# f2838x_cm_aes_ss_regs register map
Vendor: Texas Instruments
Peripheral module from a debugger description file (folder C2000).
Address unit: 16 bits
Registers are 32-bit, read-write, no defined reset value unless marked. A register's access mark holds for its fields unless they carry their own. Offsets are as the file gives them; lines under a group give offsets from that group; [hi:lo] are bit positions; {n}, {i} and the like mark numbered series; 'fields as' and 'values as' point back to an identical list; <NAME> marks a mode.

## AES_SS_REGS — AES SS Registers
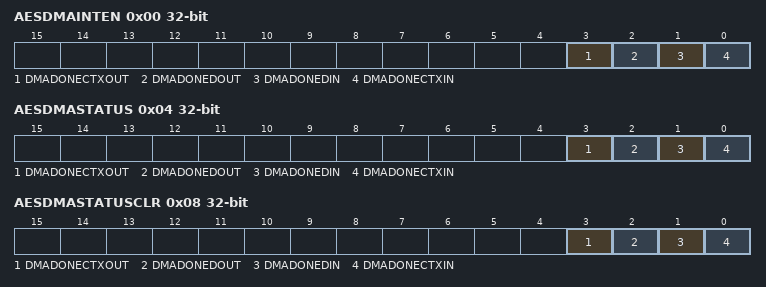
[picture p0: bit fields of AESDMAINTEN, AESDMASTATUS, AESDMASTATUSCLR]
0x00 AESDMAINTEN — DMA Done Interrupt enable register
  [3] DMADONECTXOUT — Enable bit for DMADONECTXOUT
  [2] DMADONEDOUT — Enable bit for DMADONEDOUT
  [1] DMADONEDIN — Enable bit for DMADONEDIN
  [0] DMADONECTXIN — Enable bit for DMADONECTXIN
0x04 AESDMASTATUS ro — DMA Done Interrupt status register
  [3] DMADONECTXOUT — Status bit for DMADONECTXOUT
  [2] DMADONEDOUT — Status bit for DMADONEDOUT
  [1] DMADONEDIN — Status bit for DMADONEDIN
  [0] DMADONECTXIN — Status bit for DMADONECTXIN
0x08 AESDMASTATUSCLR — DMA Done Interrupt status clear register
  [3] DMADONECTXOUT — Clear bit for AESDMASTSTAUS.DMADONECTXOUT
  [2] DMADONEDOUT — Clear bit for AESDMASTSTAUS.DMADONEDOUT
  [1] DMADONEDIN — Clear bit for AESDMASTSTAUS.DMADONEDIN
  [0] DMADONECTXIN — Clear bit for AESDMASTSTAUS.DMADONECTXIN
